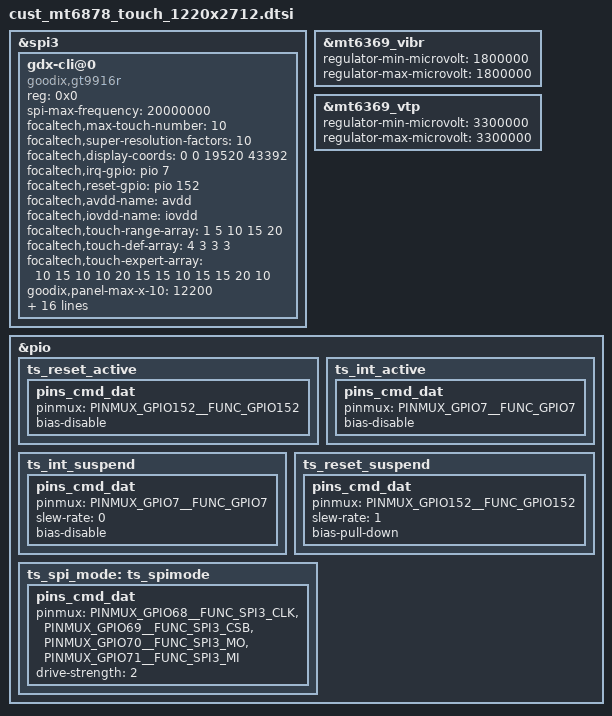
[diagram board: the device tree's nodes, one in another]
// SPDX-License-Identifier: (GPL-2.0 OR MIT)
/*
 * Copyright (C) 2020 MediaTek Inc.
 */

/* TOUCH start */
&spi3 {
	status = "okay";
	#address-cells = <1>;
	#size-cells = <0>;

	gdx-cli@0 {
		status = "ok";
		compatible = "goodix,gt9916r","focaltech_ts";
		reg = <0x0>;
		spi-max-frequency = <20000000>;

		/* 1st supply from focal3680 */

		focaltech,max-touch-number = <10>;
		focaltech,super-resolution-factors = <10>;  //10   add wanglongfei 0504
		focaltech,display-coords =  <0 0 19520 43392>;
		//focaltech,display-coords =  <0 0 1220 2712>;
		focaltech,irq-gpio = <&pio 7 0x2002>;
		focaltech,reset-gpio = <&pio 152 0x00>;
		focaltech,avdd-name = "avdd";
		focaltech,iovdd-name = "iovdd";
		focaltech,touch-range-array = <1 5 10 15 20>;
		focaltech,touch-def-array = <4 3 3 3>;
		focaltech,touch-expert-array = <10 15 10 10
						20 15 15 10
						15 15 20 10>;

		/* use pinctrl instead of direct gpio,follow are not necessary
		 * focaltech,dvdd-gpio = <&pio 110 0x00>;
		 * focaltech,dvdd-gpio-name = "fts_dvdd";
		 */


		goodix,panel-max-x-10 = <12200>;
		goodix,panel-max-y-10 = <27120>;
		goodix,panel-max-x-16 = <19520>;
		goodix,panel-max-y-16 = <43392>;
		goodix,panel-max-w = <256>;
		goodix,reset-gpio = <&pio 152 0x0>;
		goodix,irq-gpio = <&pio 7 0x2002>;
		goodix,irq-flags = <0x2002>; /* 1:trigger rising, 2:trigger falling;*/
		//goodix,avdd-gpio = <&pio 189 0x0>;
		goodix,iovdd-name = "iovdd";
		iovdd-supply = <&mt6369_vibr>;
		goodix,avdd-name = "avdd";
		avdd-supply = <&mt6369_vtp>;
		goodix,firmware-name = "goodix_firmware.bin";
		goodix,config-name = "goodix_cfg_group.bin";

		pinctrl-names = "pmx_ts_active", "pmx_ts_suspend", "pmx_ts_spi_mode";
		pinctrl-0 = <&ts_reset_active &ts_int_active>;
		pinctrl-1 = <&ts_int_suspend &ts_reset_suspend>;
		pinctrl-2 = <&ts_spi_mode>;

	};
};

&mt6369_vibr {
	regulator-min-microvolt = <1800000>;
	regulator-max-microvolt = <1800000>;
//	regulator-always-on;
};

&mt6369_vtp {
	regulator-min-microvolt = <3300000>;
	regulator-max-microvolt = <3300000>;
//	regulator-always-on;
};

&pio{
	ts_reset_active: ts_reset_active {
		pins_cmd_dat {
			pinmux = <PINMUX_GPIO152__FUNC_GPIO152>;
			bias-disable;
		};
	};
	ts_int_active: ts_int_active {
		pins_cmd_dat {
			pinmux = <PINMUX_GPIO7__FUNC_GPIO7>;
			bias-disable;
		};
	};
	ts_int_suspend: ts_int_suspend {
		pins_cmd_dat {
			pinmux = <PINMUX_GPIO7__FUNC_GPIO7>;
			slew-rate = <0>;
			bias-disable;
		};
	};
	ts_reset_suspend: ts_reset_suspend {
		pins_cmd_dat {
			pinmux = <PINMUX_GPIO152__FUNC_GPIO152>;
			slew-rate = <1>;
			bias-pull-down;
		};
	};
	ts_spi_mode: ts_spimode {
		pins_cmd_dat {
			pinmux = <PINMUX_GPIO68__FUNC_SPI3_CLK>,
				<PINMUX_GPIO69__FUNC_SPI3_CSB>,
				<PINMUX_GPIO70__FUNC_SPI3_MO>,
				<PINMUX_GPIO71__FUNC_SPI3_MI>;
			drive-strength = <2>;
		};
	};
};
/* TOUCH end */
